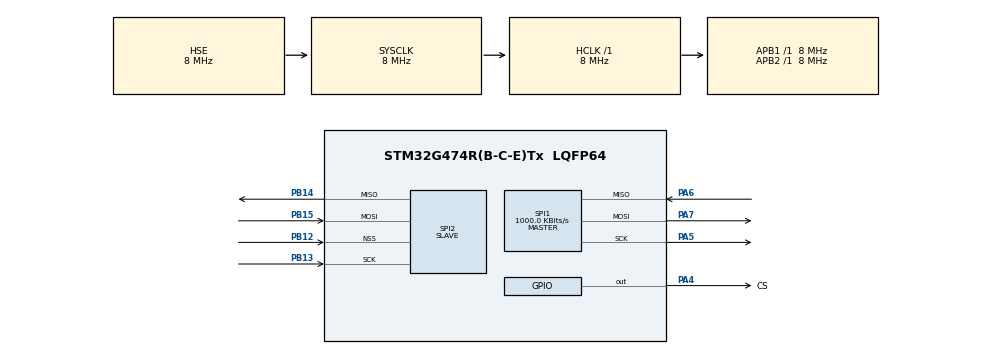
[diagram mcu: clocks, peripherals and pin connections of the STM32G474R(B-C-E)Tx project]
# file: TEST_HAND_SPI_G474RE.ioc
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Dma.Request0=SPI2_RX
Dma.SPI2_RX.0.Direction=DMA_PERIPH_TO_MEMORY
Dma.SPI2_RX.0.EventEnable=DISABLE
Dma.SPI2_RX.0.Instance=DMA1_Channel1
Dma.SPI2_RX.0.MemDataAlignment=DMA_MDATAALIGN_BYTE
Dma.SPI2_RX.0.MemInc=DMA_MINC_ENABLE
Dma.SPI2_RX.0.Mode=DMA_CIRCULAR
Dma.SPI2_RX.0.PeriphDataAlignment=DMA_PDATAALIGN_BYTE
Dma.SPI2_RX.0.PeriphInc=DMA_PINC_DISABLE
Dma.SPI2_RX.0.Polarity=HAL_DMAMUX_REQ_GEN_RISING
Dma.SPI2_RX.0.Priority=DMA_PRIORITY_LOW
Dma.SPI2_RX.0.RequestNumber=1
Dma.SPI2_RX.0.SignalID=NONE
Dma.SPI2_RX.0.SyncEnable=DISABLE
Dma.SPI2_RX.0.SyncPolarity=HAL_DMAMUX_SYNC_NO_EVENT
Dma.SPI2_RX.0.SyncRequestNumber=1
Dma.SPI2_RX.0.SyncSignalID=NONE
Mcu.Family=STM32G4
Mcu.Name=STM32G474R(B-C-E)Tx
Mcu.Package=LQFP64
NVIC.DMA1_Channel1_IRQn=true\:0\:0\:false\:false\:true\:false\:true\:true
NVIC.PriorityGroup=NVIC_PRIORITYGROUP_4
NVIC.SPI1_IRQn=true\:0\:0\:false\:false\:true\:true\:true\:true
NVIC.SPI2_IRQn=true\:0\:0\:false\:false\:true\:true\:true\:true
NVIC.TIM2_IRQn=true\:0\:0\:false\:false\:true\:true\:true\:true
PA13.Mode=Serial_Wire
PA13.Signal=SYS_JTMS-SWDIO
PA14.Mode=Serial_Wire
PA14.Signal=SYS_JTCK-SWCLK
PA4.GPIO_Label=CS
PA4.PinState=GPIO_PIN_SET
PA4.Signal=GPIO_Output
PA5.Mode=Full_Duplex_Master
PA5.Signal=SPI1_SCK
PA6.Mode=Full_Duplex_Master
PA6.Signal=SPI1_MISO
PA7.Mode=Full_Duplex_Master
PA7.Signal=SPI1_MOSI
PB12.Mode=NSS_Signal_Hard_Input
PB12.Signal=SPI2_NSS
PB13.Mode=Full_Duplex_Slave
PB13.Signal=SPI2_SCK
PB14.Mode=Full_Duplex_Slave
PB14.Signal=SPI2_MISO
PB15.Mode=Full_Duplex_Slave
PB15.Signal=SPI2_MOSI
PF0-OSC_IN.Mode=HSE-External-Oscillator
PF0-OSC_IN.Signal=RCC_OSC_IN
PF1-OSC_OUT.Mode=HSE-External-Oscillator
PF1-OSC_OUT.Signal=RCC_OSC_OUT
ProjectManager.HeapSize=0x200
ProjectManager.StackSize=0x400
ProjectManager.TargetToolchain=STM32CubeIDE
RCC.ADC12Freq_Value=8000000
RCC.ADC345Freq_Value=8000000
RCC.AHBFreq_Value=8000000
RCC.APB1Freq_Value=8000000
RCC.APB1TimFreq_Value=8000000
RCC.APB2Freq_Value=8000000
RCC.APB2TimFreq_Value=8000000
RCC.CortexFreq_Value=8000000
RCC.EXTERNAL_CLOCK_VALUE=12288000
RCC.HCLKFreq_Value=8000000
RCC.HSE_VALUE=8000000
RCC.HSI48_VALUE=48000000
RCC.HSI_VALUE=16000000
RCC.LSE_VALUE=32768
RCC.SYSCLKFreq_VALUE=8000000
RCC.SYSCLKSource=RCC_SYSCLKSOURCE_HSE
RCC.USBFreq_Value=64000000
RCC.VCOOutputFreq_Value=128000000
SPI1.BaudRatePrescaler=SPI_BAUDRATEPRESCALER_8
SPI1.CalculateBaudRate=1000.0 KBits/s
SPI1.DataSize=SPI_DATASIZE_8BIT
SPI1.Direction=SPI_DIRECTION_2LINES
SPI1.Mode=SPI_MODE_MASTER
SPI1.VirtualType=VM_MASTER
SPI2.DataSize=SPI_DATASIZE_8BIT
SPI2.Direction=SPI_DIRECTION_2LINES
SPI2.Mode=SPI_MODE_SLAVE
SPI2.VirtualNSS=VM_NSSHARD
SPI2.VirtualType=VM_SLAVE
TIM2.PeriodNoDither=9
TIM2.Prescaler=7999
VP_SYS_VS_DBSignals.Mode=DisableDeadBatterySignals
VP_TIM2_VS_ClockSourceINT.Mode=Internal
board=custom

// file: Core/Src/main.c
/* USER CODE BEGIN Header */
/**
  ******************************************************************************
  * @file           : main.c
  * @brief          : Main program body
  ******************************************************************************
  * @attention
  *
  * Copyright (c) 2026 STMicroelectronics.
  * All rights reserved.
  *
  * This software is licensed under terms that can be found in the LICENSE file
  * in the root directory of this software component.
  * If no LICENSE file comes with this software, it is provided AS-IS.
  *
  ******************************************************************************
  */
/* USER CODE END Header */
#include "main.h"
#include <stdio.h>

/* USER CODE BEGIN Includes */
#define sizeofBuff 20

uint8_t u8_SPI1_TxBuff[sizeofBuff] = "Master KOG9" ;
uint8_t u8_SPI2_RxBuff[sizeofBuff] ;

uint8_t count ;
/* USER CODE END Includes */

SPI_HandleTypeDef hspi1;
SPI_HandleTypeDef hspi2;
DMA_HandleTypeDef hdma_spi2_rx;

TIM_HandleTypeDef htim2;

void SystemClock_Config(void);
static void MX_GPIO_Init(void);
static void MX_DMA_Init(void);
static void MX_SPI1_Init(void);
static void MX_SPI2_Init(void);
static void MX_TIM2_Init(void);

/* USER CODE BEGIN 0 */

void HAL_SPI_RxCpltCallback(SPI_HandleTypeDef *hspi)
{

	UNUSED(hspi);
	if(hspi->Instance == SPI2)
	{
		HAL_SPI_Receive_IT(&hspi2, u8_SPI2_RxBuff, sizeofBuff) ;

	}
}
/* USER CODE END 0 */

int main(void)
{

  /* MCU Configuration--------------------------------------------------------*/

  /* Reset of all peripherals, Initializes the Flash interface and the Systick. */
  HAL_Init();

  /* Configure the system clock */
  SystemClock_Config();

  /* Initialize all configured peripherals */
  MX_GPIO_Init();
  MX_DMA_Init();
  MX_SPI1_Init();
  MX_SPI2_Init();
  MX_TIM2_Init();

  //HAL_SPI_Receive_IT(&hspi2, u8_SPI2_RxBuff,sizeofBuff);
  HAL_SPI_Receive_DMA(&hspi2, u8_SPI2_RxBuff, sizeofBuff) ;

  /* Infinite loop */
  while (1)
  {
	  HAL_GPIO_WritePin(CS_GPIO_Port, CS_Pin, GPIO_PIN_RESET) ;
	  HAL_SPI_Transmit(&hspi1, u8_SPI1_TxBuff, sizeofBuff, 100) ;
	  HAL_GPIO_WritePin(CS_GPIO_Port, CS_Pin, GPIO_PIN_SET) ;
	  count++ ;
	  HAL_Delay(1000) ;

  }
}

void SystemClock_Config(void)
{
  RCC_OscInitTypeDef RCC_OscInitStruct = {0};
  RCC_ClkInitTypeDef RCC_ClkInitStruct = {0};

  /** Configure the main internal regulator output voltage
  */
  HAL_PWREx_ControlVoltageScaling(PWR_REGULATOR_VOLTAGE_SCALE1);

  /** Initializes the RCC Oscillators according to the specified parameters
  * in the RCC_OscInitTypeDef structure.
  */
  RCC_OscInitStruct.OscillatorType = RCC_OSCILLATORTYPE_HSE;
  RCC_OscInitStruct.HSEState = RCC_HSE_ON;
  RCC_OscInitStruct.PLL.PLLState = RCC_PLL_NONE;
  if (HAL_RCC_OscConfig(&RCC_OscInitStruct) != HAL_OK)
  {
    Error_Handler();
  }

  /** Initializes the CPU, AHB and APB buses clocks
  */
  RCC_ClkInitStruct.ClockType = RCC_CLOCKTYPE_HCLK|RCC_CLOCKTYPE_SYSCLK
                              |RCC_CLOCKTYPE_PCLK1|RCC_CLOCKTYPE_PCLK2;
  RCC_ClkInitStruct.SYSCLKSource = RCC_SYSCLKSOURCE_HSE;
  RCC_ClkInitStruct.AHBCLKDivider = RCC_SYSCLK_DIV1;
  RCC_ClkInitStruct.APB1CLKDivider = RCC_HCLK_DIV1;
  RCC_ClkInitStruct.APB2CLKDivider = RCC_HCLK_DIV1;

  if (HAL_RCC_ClockConfig(&RCC_ClkInitStruct, FLASH_LATENCY_0) != HAL_OK)
  {
    Error_Handler();
  }
}

static void MX_SPI1_Init(void)
{

  /* SPI1 parameter configuration*/
  hspi1.Instance = SPI1;
  hspi1.Init.Mode = SPI_MODE_MASTER;
  hspi1.Init.Direction = SPI_DIRECTION_2LINES;
  hspi1.Init.DataSize = SPI_DATASIZE_8BIT;
  hspi1.Init.CLKPolarity = SPI_POLARITY_LOW;
  hspi1.Init.CLKPhase = SPI_PHASE_1EDGE;
  hspi1.Init.NSS = SPI_NSS_SOFT;
  hspi1.Init.BaudRatePrescaler = SPI_BAUDRATEPRESCALER_8;
  hspi1.Init.FirstBit = SPI_FIRSTBIT_MSB;
  hspi1.Init.TIMode = SPI_TIMODE_DISABLE;
  hspi1.Init.CRCCalculation = SPI_CRCCALCULATION_DISABLE;
  hspi1.Init.CRCPolynomial = 7;
  hspi1.Init.CRCLength = SPI_CRC_LENGTH_DATASIZE;
  hspi1.Init.NSSPMode = SPI_NSS_PULSE_ENABLE;
  if (HAL_SPI_Init(&hspi1) != HAL_OK)
  {
    Error_Handler();
  }

}

static void MX_SPI2_Init(void)
{

  /* SPI2 parameter configuration*/
  hspi2.Instance = SPI2;
  hspi2.Init.Mode = SPI_MODE_SLAVE;
  hspi2.Init.Direction = SPI_DIRECTION_2LINES;
  hspi2.Init.DataSize = SPI_DATASIZE_8BIT;
  hspi2.Init.CLKPolarity = SPI_POLARITY_LOW;
  hspi2.Init.CLKPhase = SPI_PHASE_1EDGE;
  hspi2.Init.NSS = SPI_NSS_HARD_INPUT;
  hspi2.Init.FirstBit = SPI_FIRSTBIT_MSB;
  hspi2.Init.TIMode = SPI_TIMODE_DISABLE;
  hspi2.Init.CRCCalculation = SPI_CRCCALCULATION_DISABLE;
  hspi2.Init.CRCPolynomial = 7;
  hspi2.Init.CRCLength = SPI_CRC_LENGTH_DATASIZE;
  hspi2.Init.NSSPMode = SPI_NSS_PULSE_DISABLE;
  if (HAL_SPI_Init(&hspi2) != HAL_OK)
  {
    Error_Handler();
  }

}

static void MX_TIM2_Init(void)
{

  TIM_ClockConfigTypeDef sClockSourceConfig = {0};
  TIM_MasterConfigTypeDef sMasterConfig = {0};

  htim2.Instance = TIM2;
  htim2.Init.Prescaler = 7999;
  htim2.Init.CounterMode = TIM_COUNTERMODE_UP;
  htim2.Init.Period = 9;
  htim2.Init.ClockDivision = TIM_CLOCKDIVISION_DIV1;
  htim2.Init.AutoReloadPreload = TIM_AUTORELOAD_PRELOAD_DISABLE;
  if (HAL_TIM_Base_Init(&htim2) != HAL_OK)
  {
    Error_Handler();
  }
  sClockSourceConfig.ClockSource = TIM_CLOCKSOURCE_INTERNAL;
  if (HAL_TIM_ConfigClockSource(&htim2, &sClockSourceConfig) != HAL_OK)
  {
    Error_Handler();
  }
  sMasterConfig.MasterOutputTrigger = TIM_TRGO_RESET;
  sMasterConfig.MasterSlaveMode = TIM_MASTERSLAVEMODE_DISABLE;
  if (HAL_TIMEx_MasterConfigSynchronization(&htim2, &sMasterConfig) != HAL_OK)
  {
    Error_Handler();
  }

}

static void MX_DMA_Init(void)
{

  /* DMA controller clock enable */
  __HAL_RCC_DMAMUX1_CLK_ENABLE();
  __HAL_RCC_DMA1_CLK_ENABLE();

  /* DMA interrupt init */
  /* DMA1_Channel1_IRQn interrupt configuration */
  HAL_NVIC_SetPriority(DMA1_Channel1_IRQn, 0, 0);
  HAL_NVIC_EnableIRQ(DMA1_Channel1_IRQn);

}

static void MX_GPIO_Init(void)
{
  GPIO_InitTypeDef GPIO_InitStruct = {0};

  /* GPIO Ports Clock Enable */
  __HAL_RCC_GPIOF_CLK_ENABLE();
  __HAL_RCC_GPIOA_CLK_ENABLE();
  __HAL_RCC_GPIOB_CLK_ENABLE();

  /*Configure GPIO pin Output Level */
  HAL_GPIO_WritePin(CS_GPIO_Port, CS_Pin, GPIO_PIN_SET);

  /*Configure GPIO pin : CS_Pin */
  GPIO_InitStruct.Pin = CS_Pin;
  GPIO_InitStruct.Mode = GPIO_MODE_OUTPUT_PP;
  GPIO_InitStruct.Pull = GPIO_NOPULL;
  GPIO_InitStruct.Speed = GPIO_SPEED_FREQ_LOW;
  HAL_GPIO_Init(CS_GPIO_Port, &GPIO_InitStruct);

}

void Error_Handler(void)
{
  __disable_irq();
  while (1)
  {
  }
}
